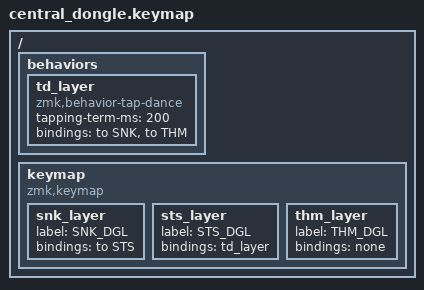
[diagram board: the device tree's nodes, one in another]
/*
 * Copyright (c) 2020 duckyb
 *
 * SPDX-License-Identifier: MIT
 */

#include <behaviors.dtsi>
#include <dt-bindings/zmk/keys.h>

#define SNK 0
#define STS 1
#define THM 2

/ {
    behaviors {
        td_layer: td_layer {
        compatible = "zmk,behavior-tap-dance";
        #binding-cells = <0>;
        tapping-term-ms = <200>;  // adjust if double taps are too slow/fast
        bindings = <&to SNK>, <&to THM>;
        };
    };

    keymap {
        compatible = "zmk,keymap";
        snk_layer {
            label = "SNK_DGL";
            bindings = <
&to STS
            >;
        };
        
        sts_layer {
            label = "STS_DGL";
            bindings = <
&td_layer
            >;
        };
        
        thm_layer {
            label = "THM_DGL";
            bindings = <
&none
            >;
        };
    };
};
